# AT32F435xx_v2 register map
Vendor: Keil; Series: AT32F435; File version: 1.0
CPU: CM4 r0p1, little endian, no MPU, FPU, 4 interrupt priority bits
Registers are 32-bit, read-write, reset 0x0 unless marked. A register's access mark holds for its fields unless they carry their own. Offsets are from the block's base; [hi:lo] are bit positions; {n}, {i} and the like mark numbered series; 'fields as' and 'values as' point back to an identical list.

## EDMA — EDMA controller
Base 0x40026000
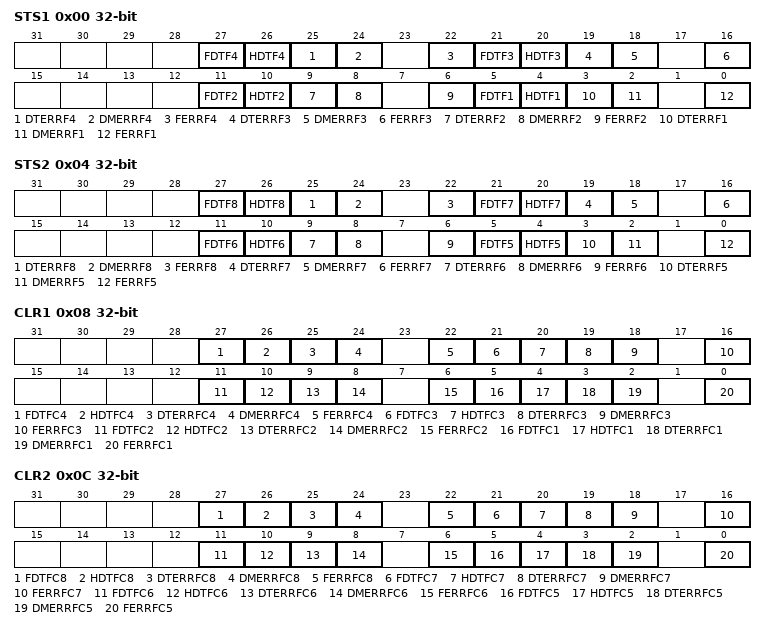
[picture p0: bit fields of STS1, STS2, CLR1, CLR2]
0x00 STS1 ro — Interrupt status register1
  [27] FDTF4 — Stream 4 Full data transfer interrupt flag
  [26] HDTF4 — Stream 4 half data transfer interrupt flag
  [25] DTERRF4 — Stream 4 transfer error interrupt flag
  [24] DMERRF4 — Stream 4 direct mode error interrupt flag
  [22] FERRF4 — Stream 4 FIFO error interrupt flag
  [21] FDTF3 — Stream 3 Full data transfer interrupt flag
  [20] HDTF3 — Stream 3 half data transfer interrupt flag
  [19] DTERRF3 — Stream 3 transfer error interrupt flag
  [18] DMERRF3 — Stream 3 direct mode error interrupt flag
  [16] FERRF3 — Stream 3 FIFO error interrupt flag
  [11] FDTF2 — Stream 2 Full data transfer interrupt flag
  [10] HDTF2 — Stream 2 half data transfer interrupt flag
  [9] DTERRF2 — Stream 2 transfer error interrupt flag
  [8] DMERRF2 — Stream 2 direct mode error interrupt flag
  [6] FERRF2 — Stream 2 FIFO error interrupt flag
  [5] FDTF1 — Stream 1 Full data transfer interrupt flag
  [4] HDTF1 — Stream 1 half data transfer interrupt flag
  [3] DTERRF1 — Stream 1 transfer error interrupt flag
  [2] DMERRF1 — Stream 1 direct mode error interrupt flag
  [0] FERRF1 — Stream 1 FIFO error interrupt flag
0x04 STS2 ro — Interrupt status register2
  [27] FDTF8 — Stream 8 full data transfer interrupt flag
  [26] HDTF8 — Stream 8 half data transfer interrupt flag
  [25] DTERRF8 — Stream 8 transfer error interrupt flag
  [24] DMERRF8 — Stream 8 direct mode error interrupt flag
  [22] FERRF8 — Stream 8 FIFO error interrupt flag
  [21] FDTF7 — Stream 7 full data transfer interrupt flag
  [20] HDTF7 — Stream 7 half data transfer interrupt flag
  [19] DTERRF7 — Stream 7 transfer error interrupt flag
  [18] DMERRF7 — Stream 7 direct mode error interrupt flag
  [16] FERRF7 — Stream 7 FIFO error interrupt flag
  [11] FDTF6 — Stream 6 full data transfer interrupt flag
  [10] HDTF6 — Stream 6 half data transfer interrupt flag
  [9] DTERRF6 — Stream 6 transfer error interrupt flag
  [8] DMERRF6 — Stream 6 direct mode error interrupt flag
  [6] FERRF6 — Stream 6 FIFO error interrupt flag
  [5] FDTF5 — Stream 5 full data transfer interrupt flag
  [4] HDTF5 — Stream 5 half data transfer interrupt flag
  [3] DTERRF5 — Stream 5 transfer error interrupt flag
  [2] DMERRF5 — Stream 5 direct mode error interrupt flag
  [0] FERRF5 — Stream 5 FIFO error interrupt flag
0x08 CLR1 — Interrupt flag clear register1
  [27] FDTFC4 — Stream 4 clear full data transfer complete interrupt flag
  [26] HDTFC4 — Stream 4 clear half data transfer interrupt flag
  [25] DTERRFC4 — Stream 4 clear transfer error interrupt flag
  [24] DMERRFC4 — Stream 4 clear direct mode error interrupt flag
  [22] FERRFC4 — Stream 4 clear FIFO error interrupt flag
  [21] FDTFC3 — Stream 3 clear full data transfer complete interrupt flag
  [20] HDTFC3 — Stream 3 clear half data transfer interrupt flag
  [19] DTERRFC3 — Stream 3 clear transfer error interrupt flag
  [18] DMERRFC3 — Stream 3 clear direct mode error interrupt flag
  [16] FERRFC3 — Stream 3 clear FIFO error interrupt flag
  [11] FDTFC2 — Stream 2 clear full data transfer complete interrupt flag
  [10] HDTFC2 — Stream 2 clear half data transfer interrupt flag
  [9] DTERRFC2 — Stream 2 clear transfer error interrupt flag
  [8] DMERRFC2 — Stream 2 clear direct mode error interrupt flag
  [6] FERRFC2 — Stream 2 clear FIFO error interrupt flag
  [5] FDTFC1 — Stream 1 clear full data transfer complete interrupt flag
  [4] HDTFC1 — Stream 1 clear half data transfer interrupt flag
  [3] DTERRFC1 — Stream 1 clear transfer error interrupt flag
  [2] DMERRFC1 — Stream 1 clear direct mode error interrupt flag
  [0] FERRFC1 — Stream 1 clear FIFO error interrupt flag
0x0C CLR2 — Interrupt flag clear register2
  [27] FDTFC8 — Stream 8 clear full data transfer complete interrupt flag
  [26] HDTFC8 — Stream 8 clear half data transfer interrupt flag
  [25] DTERRFC8 — Stream 8 clear transfer error interrupt flag
  [24] DMERRFC8 — Stream 8 clear direct mode error interrupt flag
  [22] FERRFC8 — Stream 8 clear FIFO error interrupt flag
  [21] FDTFC7 — Stream 7 clear full data transfer complete interrupt flag
  [20] HDTFC7 — Stream 7 clear half data transfer interrupt flag
  [19] DTERRFC7 — Stream 7 clear transfer error interrupt flag
  [18] DMERRFC7 — Stream 7 clear direct mode error interrupt flag
  [16] FERRFC7 — Stream 7 clear FIFO error interrupt flag
  [11] FDTFC6 — Stream 6 clear full data transfer complete interrupt flag
  [10] HDTFC6 — Stream 6 clear half data transfer interrupt flag
  [9] DTERRFC6 — Stream 6 clear transfer error interrupt flag
  [8] DMERRFC6 — Stream 6 clear direct mode error interrupt flag
  [6] FERRFC6 — Stream 6 clear FIFO error interrupt flag
  [5] FDTFC5 — Stream 5 clear full data transfer complete interrupt flag
  [4] HDTFC5 — Stream 5 clear half data transfer interrupt flag
  [3] DTERRFC5 — Stream 5 clear transfer error interrupt flag
  [2] DMERRFC5 — Stream 5 clear direct mode error interrupt flag
  [0] FERRFC5 — Stream 5 clear FIFO error interrupt flag
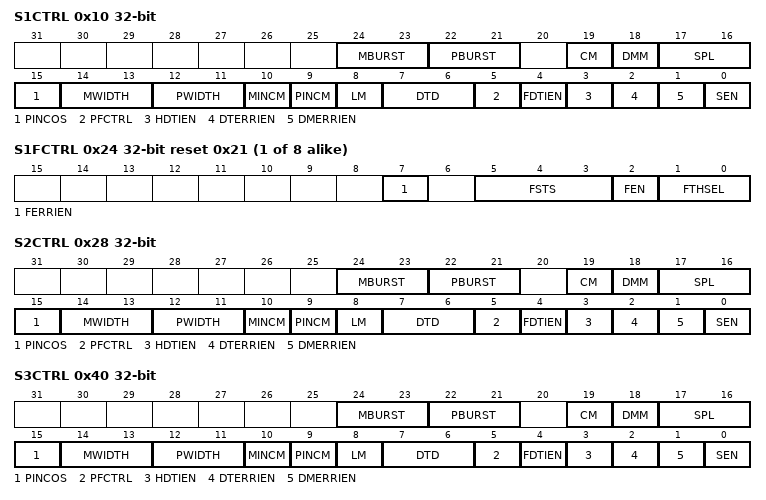
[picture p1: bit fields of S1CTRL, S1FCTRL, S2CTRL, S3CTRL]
0x10 S1CTRL — stream 1 control register
  [24:23] MBURST — Memory burst transmission
  [22:21] PBURST — Peripheral burst transmission
  [19] CM — Current memory (only in double buffer mode)
  [18] DMM — Double memory mode
  [17:16] SPL — Stream priority level
  [15] PINCOS — Peripheral increment offset size
  [14:13] MWIDTH — Memory data width
  [12:11] PWIDTH — Peripheral data width
  [10] MINCM — Memory increment mode
  [9] PINCM — Peripheral increment mode
  [8] LM — Loop mode
  [7:6] DTD — Data transfer direction
  [5] PFCTRL — Peripheral flow controller
  [4] FDTIEN — Full data transfer complete interrupt enable
  [3] HDTIEN — Half data transfer interrupt enable
  [2] DTERRIEN — Transfer error interrupt enable
  [1] DMERRIEN — Direct mode error interrupt enable
  [0] SEN — Stream enable / flag stream ready when read low
0x14 S1DTCNT — stream 1 number of data register
  [15:0] CNT — Number of data items to transfer
{0x0+0x18*i} S{i}PADDR (i=1..8) — stream {i} peripheral address register
  [31:0] PADDR — Peripheral address
{0x4+0x18*i} S{i}M0ADDR (i=1..8) — stream {i} memory 0 address register
  [31:0] M0ADDR — Memory 0 address
{0x8+0x18*i} S{i}M1ADDR (i=1..8) — stream {i} memory 1 address register
  [31:0] M1ADDR — Memory 1 address (used in case of Double buffer mode)
{0xC+0x18*i} S{i}FCTRL reset 0x21 (i=1..8) — stream {i} FIFO control register
  [7] FERRIEN — FIFO error interrupt enable
  [5:3] FSTS ro — FIFO status
  [2] FEN — FIFO mode enable
  [1:0] FTHSEL — FIFO threshold selection
0x28 S2CTRL — stream 2 control register
  fields as S1CTRL
0x2C S2DTCNT — stream 2 number of data register
  [15:0] CNT — Number of data items to transfer
0x40 S3CTRL — stream 3 control register
  fields as S1CTRL
0x44 S3DTCNT — stream 3 number of data register
  [15:0] CNT — Number of data items to transfer
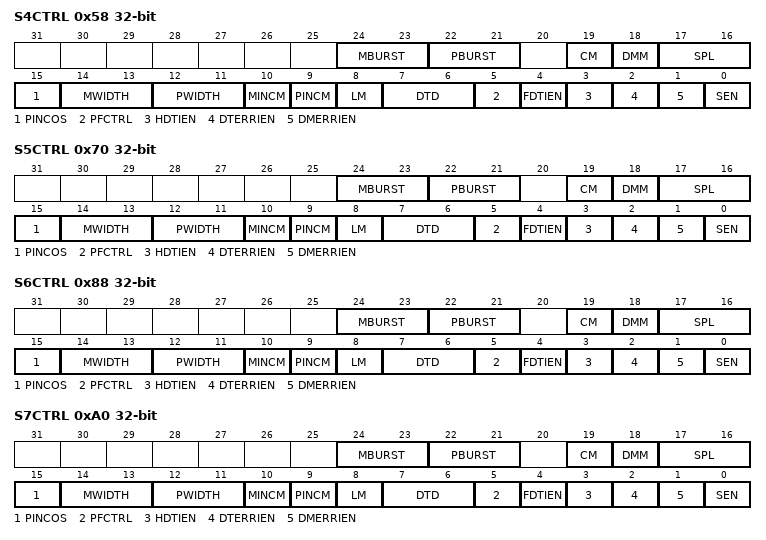
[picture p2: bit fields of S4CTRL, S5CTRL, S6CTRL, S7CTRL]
0x58 S4CTRL — stream 4 control register
  fields as S1CTRL
0x5C S4DTCNT — stream 4 number of data register
  [15:0] CNT — Number of data items to transfer
0x70 S5CTRL — stream 5 control register
  fields as S1CTRL
0x74 S5DTCNT — stream 5 number of data register
  [15:0] CNT — Number of data items to transfer
0x88 S6CTRL — stream 6 control register
  fields as S1CTRL
0x8C S6DTCNT — stream 6 number of data register
  [15:0] CNT — Number of data items to transfer
0xA0 S7CTRL — stream 7 control register
  fields as S1CTRL
0xA4 S7DTCNT — stream 7 number of data register
  [15:0] CNT — Number of data items to transfer
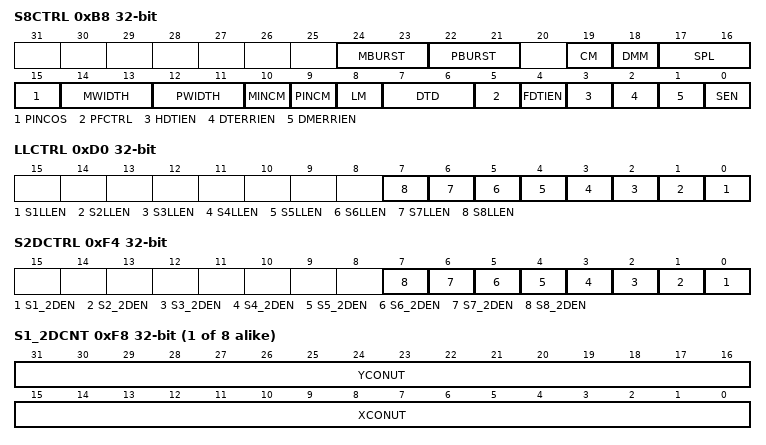
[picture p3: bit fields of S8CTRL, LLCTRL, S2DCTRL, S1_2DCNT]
0xB8 S8CTRL — stream 8 control register
  fields as S1CTRL
0xBC S8DTCNT — stream 8 number of data register
  [15:0] CNT — Number of data items to transfer
0xD0 LLCTRL — DMA Link List Control Register
  [n-1] S{n}LLEN (n=1..8) — Stream {n} link list enable
{0xD0+4i} S{i}LLP (i=1..8) — Stream {i} Link List Pointer
  [31:0] LLP — Link list pointer
0xF4 S2DCTRL — EDMA 2D Transfer Control Register
  [n-1] S{n}_2DEN (n=1..8) — Stream {n} 2D transfer enable
{0xF0+8i} S{i}_2DCNT (i=1..8) — Stream {i} 2D Transfer Count
  [31:16] YCONUT — Y dimension transfer count
  [15:0] XCONUT — X dimension transfer count
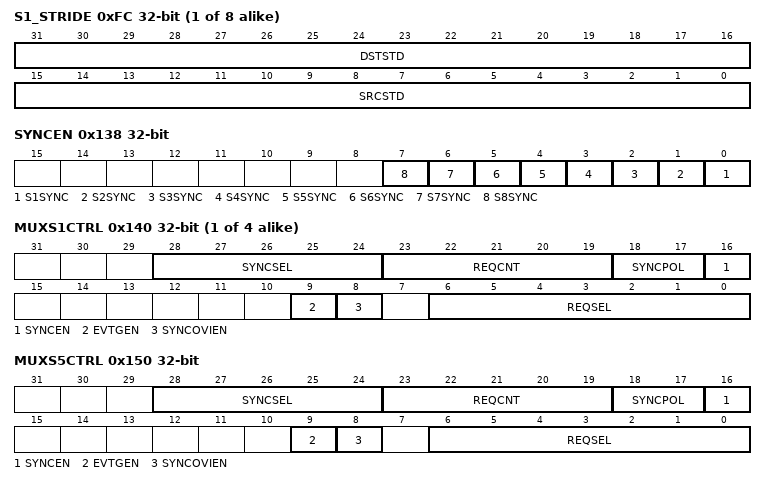
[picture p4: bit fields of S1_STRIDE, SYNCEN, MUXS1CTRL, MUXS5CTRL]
{0xF4+8i} S{i}_STRIDE (i=1..8) — Stream {i} 2D Transfer Stride
  [31:16] DSTSTD — Destination stride
  [15:0] SRCSTD — Source stride
0x138 SYNCEN — Sync Enable
  [n-1] S{n}SYNC (n=1..8) — Stream {n} sync enable
0x13C MUXSEL — EDMA MUX Table Selection
  [0] TBL_SEL — Multiplexer Table Select
{0x13C+4i} MUXS{i}CTRL (i=1..4) — Stream {i} Configuration Register
  [28:24] SYNCSEL — Synchronization select
  [23:19] REQCNT — Number of DMA requests
  [18:17] SYNCPOL — Synchronization polarity
  [16] SYNCEN — Synchroniztion enable
  [9] EVTGEN — Event generation enable
  [8] SYNCOVIEN — Synchronization overrun interrupt enable
  [6:0] REQSEL — DMA request select
0x150 MUXS5CTRL — Stream x Configuration Register
  fields as MUXS1CTRL
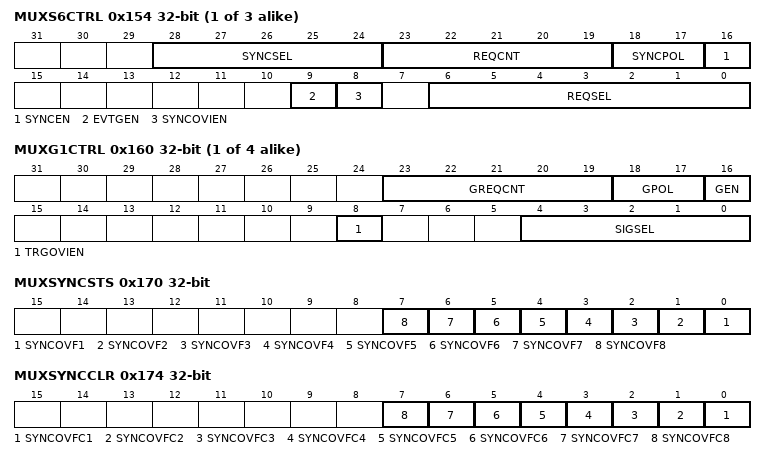
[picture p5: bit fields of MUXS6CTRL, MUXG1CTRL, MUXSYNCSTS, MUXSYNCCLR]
{0x13C+4i} MUXS{i}CTRL (i=6..8) — Stream {i} Configuration Register
  fields as MUXS1CTRL
{0x15C+4i} MUXG{i}CTRL (i=1..4) — Generator {i} Configuration Register
  [23:19] GREQCNT — Number of DMA requests to be generated
  [18:17] GPOL — DMA request generator trigger polarity
  [16] GEN — DMA request generator enable
  [8] TRGOVIEN — Trigger overrun interrupt enable
  [4:0] SIGSEL — Signal select
0x170 MUXSYNCSTS — Channel Interrupt Status Register
  [n-1] SYNCOVF{n} ro (n=1..8) — Synchronizaton overrun interrupt flag
0x174 MUXSYNCCLR — Channel Interrupt Clear Flag Register
  [n-1] SYNCOVFC{n} (n=1..8) — Clear synchronizaton overrun interrupt flag
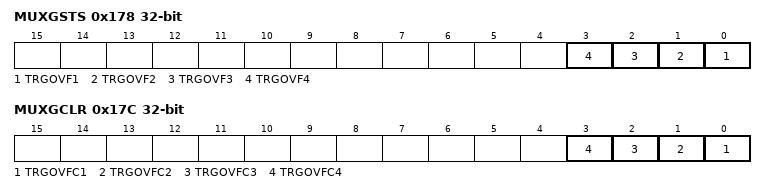
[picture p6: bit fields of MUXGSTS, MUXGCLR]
0x178 MUXGSTS — Generator Interrupt Status Register
  [n-1] TRGOVF{n} (n=1..4) — Trigger overrun interrupt flag
0x17C MUXGCLR — Generator Interrupt Clear Flag Register
  [n-1] TRGOVFC{n} (n=1..4) — Clear trigger overrun interrupt flag

## Notices in the file
Copyright (C) 2012-2014 ARM Limited. All rights reserved.
Purpose: System Viewer Description (SVD) Example (Schema Version 1.1)
This is a description of a none-existent and incomplete device
for demonstration purposes only.
Redistribution and use in source and binary forms, with or without
modification, are permitted provided that the following conditions are met:
- Redistributions of source code must retain the above copyright
notice, this list of conditions and the following disclaimer.
- Redistributions in binary form must reproduce the above copyright
notice, this list of conditions and the following disclaimer in the
documentation and/or other materials provided with the distribution.
- Neither the name of ARM nor the names of its contributors may be used
to endorse or promote products derived from this software without
specific prior written permission.
THIS SOFTWARE IS PROVIDED BY THE COPYRIGHT HOLDERS AND CONTRIBUTORS "AS IS"
AND ANY EXPRESS OR IMPLIED WARRANTIES, INCLUDING, BUT NOT LIMITED TO, THE
IMPLIED WARRANTIES OF MERCHANTABILITY AND FITNESS FOR A PARTICULAR PURPOSE
ARE DISCLAIMED. IN NO EVENT SHALL COPYRIGHT HOLDERS AND CONTRIBUTORS BE
LIABLE FOR ANY DIRECT, INDIRECT, INCIDENTAL, SPECIAL, EXEMPLARY, OR
CONSEQUENTIAL DAMAGES (INCLUDING, BUT NOT LIMITED TO, PROCUREMENT OF
SUBSTITUTE GOODS OR SERVICES; LOSS OF USE, DATA, OR PROFITS; OR BUSINESS
INTERRUPTION) HOWEVER CAUSED AND ON ANY THEORY OF LIABILITY, WHETHER IN
CONTRACT, STRICT LIABILITY, OR TORT (INCLUDING NEGLIGENCE OR OTHERWISE)
ARISING IN ANY WAY OUT OF THE USE OF THIS SOFTWARE, EVEN IF ADVISED OF THE
POSSIBILITY OF SUCH DAMAGE.
